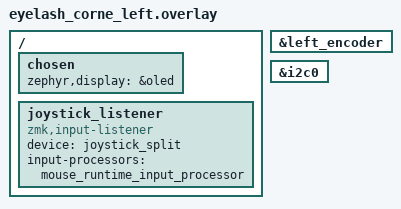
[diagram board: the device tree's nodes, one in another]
#include "eyelash_corne.dtsi"
#include <input/processors/runtime-input-processor.dtsi>
#include <behaviors/runtime_macro.dtsi>
#include <behaviors/runtime_tapdance.dtsi>

&left_encoder {
    status = "okay";
};

&i2c0 {
    status = "okay";
};

/ {
    chosen {
        zephyr,display = &oled;
    };

    joystick_listener: joystick_listener {
        compatible = "zmk,input-listener";
        device = <&joystick_split>;
        input-processors = <&mouse_runtime_input_processor>;
    };
};
